# LPC810 register map
Vendor: nxp.com; File version: 1.0
CPU: CM0PLUS r0p0, little endian, no MPU, no FPU, VTOR, 2 interrupt priority bits
Registers are 32-bit, read-write, reset 0x0 unless marked. A register's access mark holds for its fields unless they carry their own. Offsets are from the block's base; [hi:lo] are bit positions; {n}, {i} and the like mark numbered series.

## SWM0 — LPC81x SWM
Base 0x4000C000
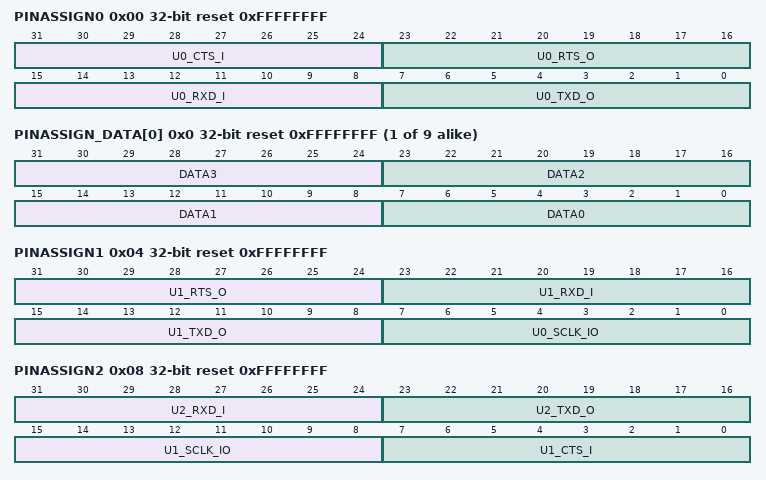
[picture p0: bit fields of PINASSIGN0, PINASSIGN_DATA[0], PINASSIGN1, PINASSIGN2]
0x00 PINASSIGN0 reset 0xFFFFFFFF (PINASSIGN_PINASSIGN_DATA view) — Pin assign register 0. Assign movable functions U0_TXD, U0_RXD, U0_RTS, U0_CTS.
  [31:24] U0_CTS_I — U0_CTS function assignment. The value is the pin number to be assigned to this function. The following pins are available: PIO0_0(= 0) to PIO0_17 (= 0x11).
  [23:16] U0_RTS_O — U0_RTS function assignment. The value is the pin number to be assigned to this function. The following pins are available: PIO0_0(= 0) to PIO0_17 (= 0x11).
  [15:8] U0_RXD_I — U0_RXD function assignment. The value is the pin number to be assigned to this function. The following pins are available: PIO0_0(= 0) to PIO0_17 (= 0x11).
  [7:0] U0_TXD_O — U0_TXD function assignment. The value is the pin number to be assigned to this function. The following pins are available: PIO0_0(= 0) to PIO0_17 (= 0x11).
{0x0+4i} PINASSIGN_DATA[{i}] (i=0..8) reset 0xFFFFFFFF (PINASSIGN_PINASSIGN_DATA view) — Pin assign register
  [31:24] DATA3 — T0_CAP2 function assignment. The value is the pin number to be assigned to this function. The following pins are available: PIO0_0 (= 0) to PIO0_31 (= 0x1F) and from PIO1_0 (=0x20) to PIO1_21(=0x35).
  [23:16] DATA2 — T0_CAP1 function assignment. The value is the pin number to be assigned to this function. The following pins are available: PIO0_0 (= 0) to PIO0_31 (= 0x1F) and from PIO1_0 (=0x20) to PIO1_21(=0x35).
  [15:8] DATA1 — T0_CAP0 function assignment. The value is the pin number to be assigned to this function. The following pins are available: PIO0_0 (= 0) to PIO0_31 (= 0x1F) and from PIO1_0 (=0x20) to PIO1_21(=0x35).
  [7:0] DATA0 — T0_MAT3 function assignment. The value is the pin number to be assigned to this function. The following pins are available: PIO0_0 (= 0) to PIO0_31 (= 0x1F) and from PIO1_0 (=0x20) to PIO1_21(=0x35).
0x04 PINASSIGN1 reset 0xFFFFFFFF (PINASSIGN_PINASSIGN_DATA view) — Pin assign register 1. Assign movable functions U0_SCLK, U1_TXD, U1_RXD, U1_RTS.
  [31:24] U1_RTS_O — U1_RTS function assignment. The value is the pin number to be assigned to this function. The following pins are available: PIO0_0(= 0) to PIO0_17 (= 0x11).
  [23:16] U1_RXD_I — U1_RXD function assignment. The value is the pin number to be assigned to this function. The following pins are available: PIO0_0(= 0) to PIO0_17 (= 0x11).
  [15:8] U1_TXD_O — U1_TXD function assignment. The value is the pin number to be assigned to this function. The following pins are available: PIO0_0(= 0) to PIO0_17 (= 0x11).
  [7:0] U0_SCLK_IO — U0_SCLK function assignment. The value is the pin number to be assigned to this function. The following pins are available: PIO0_0(= 0) to PIO0_17 (= 0x11).
0x08 PINASSIGN2 reset 0xFFFFFFFF (PINASSIGN_PINASSIGN_DATA view) — Pin assign register 2. Assign movable functions U1_CTS, U1_SCLK, U2_TXD, U2_RXD.
  [31:24] U2_RXD_I — U2_RXD function assignment. The value is the pin number to be assigned to this function. The following pins are available: PIO0_0(= 0) to PIO0_17 (= 0x11).
  [23:16] U2_TXD_O — U2_TXD function assignment. The value is the pin number to be assigned to this function. The following pins are available: PIO0_0(= 0) to PIO0_17 (= 0x11).
  [15:8] U1_SCLK_IO — U1_SCLK function assignment. The value is the pin number to be assigned to this function. The following pins are available: PIO0_0(= 0) to PIO0_17 (= 0x11).
  [7:0] U1_CTS_I — U1_CTS function assignment. The value is the pin number to be assigned to this function. The following pins are available: PIO0_0(= 0) to PIO0_17 (= 0x11).
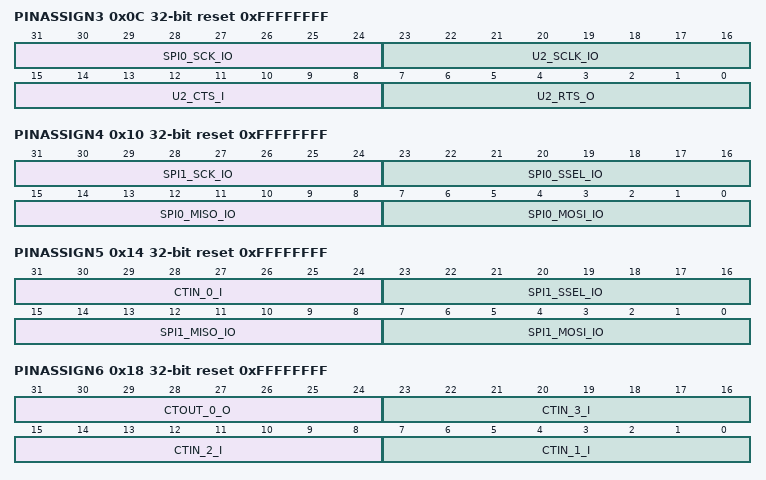
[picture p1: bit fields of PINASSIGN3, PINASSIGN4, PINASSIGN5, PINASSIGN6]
0x0C PINASSIGN3 reset 0xFFFFFFFF (PINASSIGN_PINASSIGN_DATA view) — Pin assign register 3. Assign movable function U2_RTS, U2_CTS, U2_SCLK, SPI0_SCK.
  [31:24] SPI0_SCK_IO — SPI0_SCK function assignment. The value is the pin number to be assigned to this function. The following pins are available: PIO0_0(= 0) to PIO0_17 (= 0x11).
  [23:16] U2_SCLK_IO — U2_SCLK function assignment. The value is the pin number to be assigned to this function. The following pins are available: PIO0_0(= 0) to PIO0_17 (= 0x11).
  [15:8] U2_CTS_I — U2_CTS function assignment. The value is the pin number to be assigned to this function. The following pins are available: PIO0_0(= 0) to PIO0_17 (= 0x11).
  [7:0] U2_RTS_O — U2_RTS function assignment. The value is the pin number to be assigned to this function. The following pins are available: PIO0_0(= 0) to PIO0_17 (= 0x11).
0x10 PINASSIGN4 reset 0xFFFFFFFF (PINASSIGN_PINASSIGN_DATA view) — Pin assign register 4. Assign movable functions SPI0_MOSI, SPI0_MISO,SPI0_SSEL, SPI1_SCK.
  [31:24] SPI1_SCK_IO — SPI1_SCK function assignment. The value is the pin number to be assigned to this function. The following pins are available: PIO0_0(= 0) to PIO0_17 (= 0x11).
  [23:16] SPI0_SSEL_IO — SPI0_SSEL function assignment. The value is the pin number to be assigned to this function. The following pins are available: PIO0_0(= 0) to PIO0_17 (= 0x11).
  [15:8] SPI0_MISO_IO — SPI0_MISIO function assignment. The value is the pin number to be assigned to this function. The following pins are available: PIO0_0(= 0) to PIO0_17 (= 0x11).
  [7:0] SPI0_MOSI_IO — SPI0_MOSI function assignment. The value is the pin number to be assigned to this function. The following pins are available: PIO0_0(= 0) to PIO0_17 (= 0x11).
0x14 PINASSIGN5 reset 0xFFFFFFFF (PINASSIGN_PINASSIGN_DATA view) — Pin assign register 5. Assign movable functions SPI1_MOSI, SPI1_MISO,SPI1_SSEL, CTIN_0
  [31:24] CTIN_0_I — CTIN_0 function assignment. The value is the pin number to be assigned to this function. The following pins are available: PIO0_0(= 0) to PIO0_17 (= 0x11).
  [23:16] SPI1_SSEL_IO — SPI1_SSEL function assignment. The value is the pin number to be assigned to this function. The following pins are available: PIO0_0(= 0) to PIO0_17 (= 0x11).
  [15:8] SPI1_MISO_IO — SPI1_MISIO function assignment. The value is the pin number to be assigned to this function. The following pins are available: PIO0_0(= 0) to PIO0_17 (= 0x11).
  [7:0] SPI1_MOSI_IO — SPI1_MOSI function assignment. The value is the pin number to be assigned to this function. The following pins are available: PIO0_0(= 0) to PIO0_17 (= 0x11).
0x18 PINASSIGN6 reset 0xFFFFFFFF (PINASSIGN_PINASSIGN_DATA view) — Pin assign register 6. Assign movable functions CTIN_1, CTIN_2, CTIN_3,CTOUT_0.
  [31:24] CTOUT_0_O — CTOUT_0 function assignment. The value is the pin number to be assigned to this function. The following pins are available: PIO0_0(= 0) to PIO0_17 (= 0x11).
  [23:16] CTIN_3_I — CTIN_3 function assignment. The value is the pin number to be assigned to this function. The following pins are available: PIO0_0(= 0) to PIO0_17 (= 0x11).
  [15:8] CTIN_2_I — CTIN_2 function assignment. The value is the pin number to be assigned to this function. The following pins are available: PIO0_0(= 0) to PIO0_17 (= 0x11).
  [7:0] CTIN_1_I — CTIN_1 function assignment. The value is the pin number to be assigned to this function. The following pins are available: PIO0_0(= 0) to PIO0_17 (= 0x11).
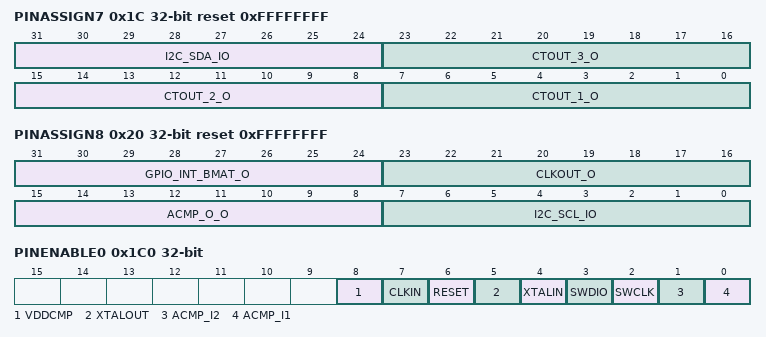
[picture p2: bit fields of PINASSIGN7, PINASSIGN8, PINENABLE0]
0x1C PINASSIGN7 reset 0xFFFFFFFF (PINASSIGN_PINASSIGN_DATA view) — Pin assign register 7. Assign movable functions CTOUT_1, CTOUT_2, CTOUT_3,I2C_SDA.
  [31:24] I2C_SDA_IO — I2C_SDA function assignment. The value is the pin number to be assigned to this function. The following pins are available: PIO0_0(= 0) to PIO0_17 (= 0x11).
  [23:16] CTOUT_3_O — CTOUT_3 function assignment. The value is the pin number to be assigned to this function. The following pins are available: PIO0_0(= 0) to PIO0_17 (= 0x11).
  [15:8] CTOUT_2_O — CTOUT_2 function assignment. The value is the pin number to be assigned to this function. The following pins are available: PIO0_0(= 0) to PIO0_17 (= 0x11).
  [7:0] CTOUT_1_O — CTOUT_1 function assignment. The value is the pin number to be assigned to this function. The following pins are available: PIO0_0(= 0) to PIO0_17 (= 0x11).
0x20 PINASSIGN8 reset 0xFFFFFFFF (PINASSIGN_PINASSIGN_DATA view) — Pin assign register 8. Assign movable functions I2C_SCL, ACMP_O, CLKOUT,GPIO_INT_BMAT.
  [31:24] GPIO_INT_BMAT_O — GPIO_INT_BMAT function assignment. The value is the pin number to be assigned to this function. The following pins are available: PIO0_0(= 0) to PIO0_17 (= 0x11).
  [23:16] CLKOUT_O — CLKOUT function assignment. The value is the pin number to be assigned to this function. The following pins are available: PIO0_0(= 0) to PIO0_17 (= 0x11).
  [15:8] ACMP_O_O — ACMP_O_O function assignment. The value is the pin number to be assigned to this function. The following pins are available: PIO0_0(= 0) to PIO0_17 (= 0x11).
  [7:0] I2C_SCL_IO — I2C_SCL function assignment. The value is the pin number to be assigned to this function. The following pins are available: PIO0_0(= 0) to PIO0_17 (= 0x11).
0x1C0 PINENABLE0 reset not defined — Pin enable register 0. Enables fixed-pin functions ACMP_I0, ACMP_I1, SWCLK, SWDIO, XTALIN, XTALOUT, RESET, CLKIN, VDDCMP and so on.
  [8] VDDCMP — Enables fixed-pin function. Writing a 1 deselects the function and any movable function can be assigned to this pin. By default the fixed--pin function is deselected and GPIO is assigned to this pin.
    0=ENABLED (Enable VDDCMP. This function is enabled on pin PIO0_6.); 1=DISABLED (Disable VDDCMP. GPIO function PIO0_6 (default) or any other movable function can be assigned to pin PIO0_6.)
  [7] CLKIN — Enables fixed-pin function. Writing a 1 deselects the function and any movable function can be assigned to this pin. By default the fixed-pin function is deselected and GPIO is assigned to this pin. Functions CLKIN and ACMP_I2 are connected to the same pin PIO0_1. To use CLKIN, disable ACMP_I2 in bit 1 of this register and enable CLKIN.
    0=ENABLED (Enable CLKIN. This function is enabled on pin PIO0_1.); 1=DISABLED (Disable CLKIN. GPIO function PIO0_1 (default) or any other movable function can be assigned to pin CLKIN.)
  [6] RESET — Enables fixed-pin function. Writing a 1 deselects the function and any movable function can be assigned to this pin. This function is selected by default.
    0=ENABLED (Enable RESET. This function is enabled on pin PIO0_5.); 1=DISABLED (Disable RESET. GPIO function PIO0_5 is selected on this pin. Any other movable function can be assigned to pin PIO0_5.)
  [5] XTALOUT — Enables fixed-pin function. Writing a 1 deselects the function and any movable function can be assigned to this pin. By default the fixed--pin function is deselected and GPIO is assigned to this pin.
    0=ENABLED (Enable XTALOUT. This function is enabled on pin PIO0_9.); 1=DISABLED (Disable XTALOUT. GPIO function PIO0_9 (default) or any other movable function can be assigned to pin PIO0_9.)
  [4] XTALIN — Enables fixed-pin function. Writing a 1 deselects the function and any movable function can be assigned to this pin. By default the fixed--pin function is deselected and GPIO is assigned to this pin.
    0=ENABLED (Enable XTALIN. This function is enabled on pin PIO0_8.); 1=DISABLED (Disable XTALIN. GPIO function PIO0_8 (default) or any other movable function can be assigned to pin PIO0_8.)
  [3] SWDIO — Enables fixed-pin function. Writing a 1 deselects the function and any movable function can be assigned to this pin. This function is selected by default.
    0=ENABLED (Enable SWDIO. This function is enabled on pin PIO0_2.); 1=DISABLED (Disable SWDIO. GPIO function PIO0_2 is selected on this pin. Any other movable function can be assigned to pin PIO0_2.)
  [2] SWCLK — Enables fixed-pin function. Writing a 1 deselects the function and any movable function can be assigned to this pin. This function is selected by default.
    0=ENABLED (Enable SWCLK. This function is enabled on pin PIO0_3.); 1=DISABLED (Disable SWCLK. GPIO function PIO0_3 is selected on this pin. Any other movable function can be assigned to pin PIO0_3.)
  [1] ACMP_I2 — Enables fixed-pin function. Writing a 1 deselects the function and any movable function can be assigned to this pin. By default the fixed-pin function is deselected and GPIO is assigned to this pin. Functions CLKIN and ACMP_I2 are connected to the same pin PIO0_1. To use ACMP_I2, disable the CLKIN function in bit 7 of this register and enable ACMP_I2.
    0=Enable ACMP_I2. This function is enabled on pin PIO0_1.; 1=Disable ACMP_I2. GPIO function PIO0_1 (default) or any other movable function can be assigned to pin PIO0_1.
  [0] ACMP_I1 — Enables fixed-pin function. Writing a 1 deselects the function and any movable function can be assigned to this pin. By default the fixed--pin function is deselected and GPIO is assigned to this pin.
    0=ENABLED (Enable ACMP_I1. This function is enabled on pin PIO0_0.); 1=DISABLED (Disable ACMP_I1. GPIO function PIO0_0 (default) or any other movable function can be assigned to pin PIO0_0.)

## Notices in the file
The Clear BSD License
Copyright 2016-2018 NXP
All rights reserved.
Redistribution and use in source and binary forms, with or without
modification, are permitted (subject to the limitations in the
disclaimer below) provided that the following conditions are met:
Redistributions of source code must retain the above copyright
notice, this list of conditions and the following disclaimer.
Redistributions in binary form must reproduce the above copyright
notice, this list of conditions and the following disclaimer in the
documentation and/or other materials provided with the distribution.
Neither the name of the copyright holder nor the names of its
contributors may be used to endorse or promote products derived from
this software without specific prior written permission.
NO EXPRESS OR IMPLIED LICENSES TO ANY PARTY'S PATENT RIGHTS ARE
GRANTED BY THIS LICENSE. THIS SOFTWARE IS PROVIDED BY THE COPYRIGHT
HOLDERS AND CONTRIBUTORS "AS IS" AND ANY EXPRESS OR IMPLIED
WARRANTIES, INCLUDING, BUT NOT LIMITED TO, THE IMPLIED WARRANTIES OF
MERCHANTABILITY AND FITNESS FOR A PARTICULAR PURPOSE ARE
DISCLAIMED. IN NO EVENT SHALL THE COPYRIGHT HOLDER OR CONTRIBUTORS BE
LIABLE FOR ANY DIRECT, INDIRECT, INCIDENTAL, SPECIAL, EXEMPLARY, OR
CONSEQUENTIAL DAMAGES (INCLUDING, BUT NOT LIMITED TO, PROCUREMENT OF
SUBSTITUTE GOODS OR SERVICES; LOSS OF USE, DATA, OR PROFITS; OR
BUSINESS INTERRUPTION) HOWEVER CAUSED AND ON ANY THEORY OF LIABILITY,
WHETHER IN CONTRACT, STRICT LIABILITY, OR TORT (INCLUDING NEGLIGENCE
OR OTHERWISE) ARISING IN ANY WAY OUT OF THE USE OF THIS SOFTWARE, EVEN
IF ADVISED OF THE POSSIBILITY OF SUCH DAMAGE.
